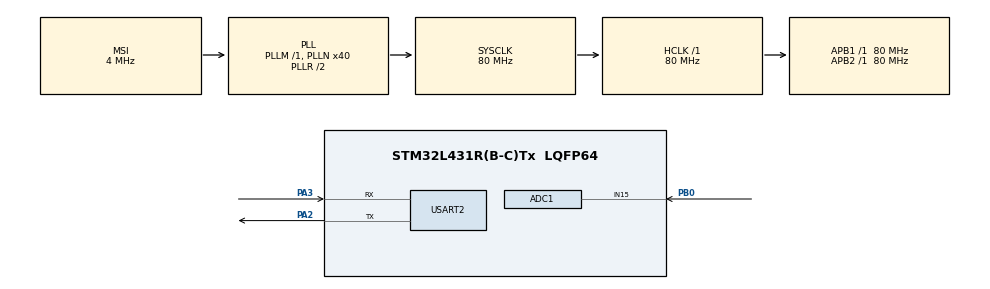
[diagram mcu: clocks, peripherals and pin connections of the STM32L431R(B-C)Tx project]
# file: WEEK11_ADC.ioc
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ADC1.Channel-1\#ChannelRegularConversion=ADC_CHANNEL_15
ADC1.ClockPrescaler=ADC_CLOCK_ASYNC_DIV2
ADC1.ContinuousConvMode=ENABLE
ADC1.DMAContinuousRequests=ENABLE
ADC1.NbrOfConversionFlag=1
ADC1.OffsetNumber-1\#ChannelRegularConversion=ADC_OFFSET_NONE
ADC1.Rank-1\#ChannelRegularConversion=1
ADC1.SamplingTime-1\#ChannelRegularConversion=ADC_SAMPLETIME_640CYCLES_5
ADC1.master=1
Dma.ADC1.0.Direction=DMA_PERIPH_TO_MEMORY
Dma.ADC1.0.Instance=DMA1_Channel1
Dma.ADC1.0.MemDataAlignment=DMA_MDATAALIGN_WORD
Dma.ADC1.0.MemInc=DMA_MINC_ENABLE
Dma.ADC1.0.Mode=DMA_CIRCULAR
Dma.ADC1.0.PeriphDataAlignment=DMA_PDATAALIGN_WORD
Dma.ADC1.0.PeriphInc=DMA_PINC_DISABLE
Dma.ADC1.0.Priority=DMA_PRIORITY_HIGH
Dma.Request0=ADC1
Mcu.Family=STM32L4
Mcu.Name=STM32L431R(B-C)Tx
Mcu.Package=LQFP64
NVIC.ADC1_IRQn=true\:0\:0\:false\:false\:true\:true\:true\:true
NVIC.DMA1_Channel1_IRQn=true\:0\:0\:false\:false\:true\:false\:true\:true
NVIC.PriorityGroup=NVIC_PRIORITYGROUP_4
PA13\ (JTMS-SWDIO).Mode=Serial_Wire
PA13\ (JTMS-SWDIO).Signal=SYS_JTMS-SWDIO
PA14\ (JTCK-SWCLK).Mode=Serial_Wire
PA14\ (JTCK-SWCLK).Signal=SYS_JTCK-SWCLK
PA2.Mode=Asynchronous
PA2.Signal=USART2_TX
PA3.Mode=Asynchronous
PA3.Signal=USART2_RX
PB0.Signal=ADCx_IN15
ProjectManager.HeapSize=0x200
ProjectManager.StackSize=0x400
ProjectManager.TargetToolchain=MDK-ARM V5.32
RCC.ADCFreq_Value=12000000
RCC.AHBFreq_Value=80000000
RCC.APB1Freq_Value=80000000
RCC.APB1TimFreq_Value=80000000
RCC.APB2Freq_Value=80000000
RCC.APB2TimFreq_Value=80000000
RCC.CortexFreq_Value=80000000
RCC.HCLKFreq_Value=80000000
RCC.HSE_VALUE=8000000
RCC.HSI48_VALUE=48000000
RCC.HSI_VALUE=16000000
RCC.LSE_VALUE=32768
RCC.MSI_VALUE=4000000
RCC.PLLN=40
RCC.PLLSAI1N=18
RCC.PLLSAI1R=RCC_PLLR_DIV6
RCC.SYSCLKFreq_VALUE=80000000
RCC.SYSCLKSource=RCC_SYSCLKSOURCE_PLLCLK
RCC.VCOOutputFreq_Value=160000000
SH.ADCx_IN15.0=ADC1_IN15,IN15-Single-Ended
USART2.VirtualMode-Asynchronous=VM_ASYNC
board=custom

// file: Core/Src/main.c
/* USER CODE BEGIN Header */
/**
  ******************************************************************************
  * @file           : main.c
  * @brief          : Main program body
  ******************************************************************************
  * @attention
  *
  * Copyright (c) 2022 STMicroelectronics.
  * All rights reserved.
  *
  * This software is licensed under terms that can be found in the LICENSE file
  * in the root directory of this software component.
  * If no LICENSE file comes with this software, it is provided AS-IS.
  *
  ******************************************************************************
  */
/* USER CODE END Header */
#include "main.h"
#include "adc.h"
#include "dma.h"
#include "usart.h"
#include "gpio.h"

/* USER CODE BEGIN Includes */
#include "stdio.h"
/* USER CODE END Includes */

/* USER CODE BEGIN PV */
uint16_t adcValue = 0;
float voltage = 0;
uint8_t tData[] = "Welcome to 222 for STM32!";
/* USER CODE END PV */

void SystemClock_Config(void);

int main(void)
{

  /* MCU Configuration--------------------------------------------------------*/

  /* Reset of all peripherals, Initializes the Flash interface and the Systick. */
  HAL_Init();

  /* Configure the system clock */
  SystemClock_Config();

  /* Initialize all configured peripherals */
  MX_GPIO_Init();
  MX_DMA_Init();
  MX_ADC1_Init();
  MX_USART2_UART_Init();
  /* USER CODE BEGIN 2 */
	HAL_ADC_Start_DMA(&hadc1, (uint32_t *)&adcValue, 1);
  /* USER CODE END 2 */

  /* Infinite loop */
  while (1)
  {
		voltage = adcValue * 3.3 / 4096;
		printf("adcValue: %d, voltage: %f\n", adcValue, voltage);
		HAL_Delay(1000);
  }
}

void SystemClock_Config(void)
{
  RCC_OscInitTypeDef RCC_OscInitStruct = {0};
  RCC_ClkInitTypeDef RCC_ClkInitStruct = {0};

  /** Configure the main internal regulator output voltage
  */
  if (HAL_PWREx_ControlVoltageScaling(PWR_REGULATOR_VOLTAGE_SCALE1) != HAL_OK)
  {
    Error_Handler();
  }

  /** Initializes the RCC Oscillators according to the specified parameters
  * in the RCC_OscInitTypeDef structure.
  */
  RCC_OscInitStruct.OscillatorType = RCC_OSCILLATORTYPE_MSI;
  RCC_OscInitStruct.MSIState = RCC_MSI_ON;
  RCC_OscInitStruct.MSICalibrationValue = 0;
  RCC_OscInitStruct.MSIClockRange = RCC_MSIRANGE_6;
  RCC_OscInitStruct.PLL.PLLState = RCC_PLL_ON;
  RCC_OscInitStruct.PLL.PLLSource = RCC_PLLSOURCE_MSI;
  RCC_OscInitStruct.PLL.PLLM = 1;
  RCC_OscInitStruct.PLL.PLLN = 40;
  RCC_OscInitStruct.PLL.PLLP = RCC_PLLP_DIV7;
  RCC_OscInitStruct.PLL.PLLQ = RCC_PLLQ_DIV2;
  RCC_OscInitStruct.PLL.PLLR = RCC_PLLR_DIV2;
  if (HAL_RCC_OscConfig(&RCC_OscInitStruct) != HAL_OK)
  {
    Error_Handler();
  }

  /** Initializes the CPU, AHB and APB buses clocks
  */
  RCC_ClkInitStruct.ClockType = RCC_CLOCKTYPE_HCLK|RCC_CLOCKTYPE_SYSCLK
                              |RCC_CLOCKTYPE_PCLK1|RCC_CLOCKTYPE_PCLK2;
  RCC_ClkInitStruct.SYSCLKSource = RCC_SYSCLKSOURCE_PLLCLK;
  RCC_ClkInitStruct.AHBCLKDivider = RCC_SYSCLK_DIV1;
  RCC_ClkInitStruct.APB1CLKDivider = RCC_HCLK_DIV1;
  RCC_ClkInitStruct.APB2CLKDivider = RCC_HCLK_DIV1;

  if (HAL_RCC_ClockConfig(&RCC_ClkInitStruct, FLASH_LATENCY_4) != HAL_OK)
  {
    Error_Handler();
  }
}

void Error_Handler(void)
{
  __disable_irq();
  while (1)
  {
  }
}
